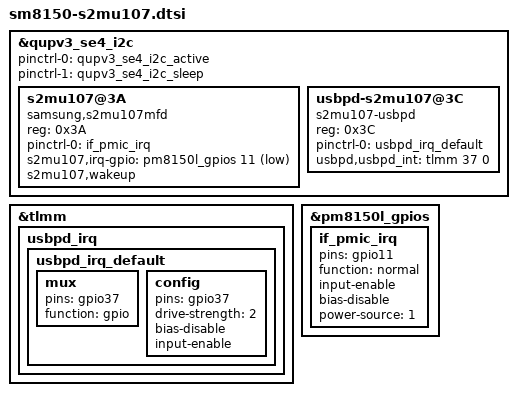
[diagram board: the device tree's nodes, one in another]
/* Copyright (c) 2018, The Linux Foundation. All rights reserved.
 *
 * This program is free software; you can redistribute it and/or modify
 * it under the terms of the GNU General Public License version 2 and
 * only version 2 as published by the Free Software Foundation.
 *
 * This program is distributed in the hope that it will be useful,
 * but WITHOUT ANY WARRANTY; without even the implied warranty of
 * MERCHANTABILITY or FITNESS FOR A PARTICULAR PURPOSE.  See the
 * GNU General Public License for more details.
 */

&qupv3_se4_i2c {
	status = "ok";

	pinctrl-names = "default", "sleep";
	pinctrl-0 = <&qupv3_se4_i2c_active>;
	pinctrl-1 = <&qupv3_se4_i2c_sleep>;

	s2mu107@3A {
			status = "okay";
			compatible = "samsung,s2mu107mfd";
			reg = <0x3A>;
			pinctrl-names = "default";
			pinctrl-0 = <&if_pmic_irq>;
			s2mu107,irq-gpio = <&pm8150l_gpios 11 0x01>;
			s2mu107,wakeup;
	};

	usbpd-s2mu107@3C {
			status = "okay";
			compatible = "s2mu107-usbpd";
			reg = <0x3C>;
			pinctrl-names = "default";
			pinctrl-0     = <&usbpd_irq_default>;
			usbpd,usbpd_int = <&tlmm 37 0>;
	};
};



&tlmm {
	usbpd_irq {
		usbpd_irq_default: usbpd_irq_default {
			mux {
				pins = "gpio37";
				function = "gpio";
			};
			config {
				pins = "gpio37";
				drive-strength = <2>;   /* 16 mA */
				bias-disable;
				input-enable;
			};
		};
	};
};

&pm8150l_gpios {
	if_pmic_irq: if_pmic_irq {
		pins = "gpio11";
		function = "normal";
		input-enable;
		bias-disable;
		power-source = <1>;
	};
};
